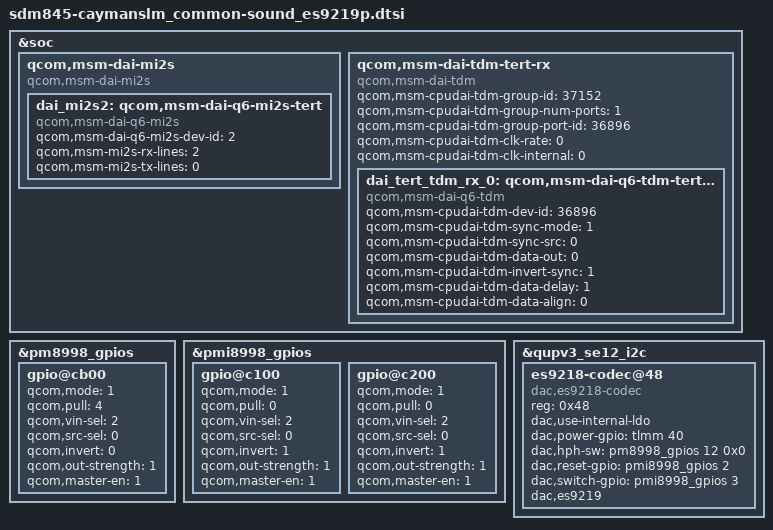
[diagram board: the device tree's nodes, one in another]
/* Copyright (c) 2017, The Linux Foundation. All rights reserved.
 *
 * This program is free software; you can redistribute it and/or modify
 * it under the terms of the GNU General Public License version 2 and
 * only version 2 as published by the Free Software Foundation.
 *
 * This program is distributed in the hope that it will be useful,
 * but WITHOUT ANY WARRANTY; without even the implied warranty of
 * MERCHANTABILITY or FITNESS FOR A PARTICULAR PURPOSE.  See the
 * GNU General Public License for more details.
 */

&soc {
	qcom,msm-dai-mi2s {
		compatible = "qcom,msm-dai-mi2s";
		dai_mi2s2: qcom,msm-dai-q6-mi2s-tert {
                       compatible = "qcom,msm-dai-q6-mi2s";
                       qcom,msm-dai-q6-mi2s-dev-id = <2>;
                       qcom,msm-mi2s-rx-lines = <2>; /* SD1 used as output */
                       qcom,msm-mi2s-tx-lines = <0>; /* SD0 used as input */
		};
	};

	qcom,msm-dai-tdm-tert-rx {
		compatible = "qcom,msm-dai-tdm";
		qcom,msm-cpudai-tdm-group-id = <37152>;
		qcom,msm-cpudai-tdm-group-num-ports = <1>;
		qcom,msm-cpudai-tdm-group-port-id = <36896>;
		qcom,msm-cpudai-tdm-clk-rate = <0>; // external clk
		qcom,msm-cpudai-tdm-clk-internal = <0>; /* EBIT */
		dai_tert_tdm_rx_0: qcom,msm-dai-q6-tdm-tert-rx-0 {
			compatible = "qcom,msm-dai-q6-tdm";
			qcom,msm-cpudai-tdm-dev-id = <36896>;
			qcom,msm-cpudai-tdm-sync-mode = <1>; /* long sync mode */
			qcom,msm-cpudai-tdm-sync-src = <0>; /* external source */
			qcom,msm-cpudai-tdm-data-out = <0>;
			qcom,msm-cpudai-tdm-invert-sync = <1>;
			qcom,msm-cpudai-tdm-data-delay = <1>;
			qcom,msm-cpudai-tdm-data-align = <0>;
		};
	};
};

&pm8998_gpios {
	gpio@cb00 { /* GPIO 12 - HIFI_MODE2 */
		qcom,mode = <1>;			/* Digital output */
		qcom,pull = <4>;			/* Pull down */
		qcom,vin-sel = <2>;			/* Vin 2 */
		qcom,src-sel = <0>;			/* Constant */
		qcom,invert = <0>;			/* Invert */
		qcom,out-strength = <1>;	/* Low */
		qcom,master-en = <1>;		/* Enable GPIO */
		status = "okay";
	};
};

&pmi8998_gpios {
	gpio@c100 { /* GPIO 2 - HIFI_RESET_N */
		qcom,mode = <1>;			/* Digital output*/
		qcom,pull = <0>;			/* Pull down 30uA */
		qcom,vin-sel = <2>;			/* VIN2 */
		qcom,src-sel = <0>;			/* Constant */
		qcom,invert = <1>;			/* Enable Invert */
		qcom,out-strength = <1>;	/* Low */
		qcom,master-en = <1>;		/* Enable GPIO */
		status = "okay";
	};
};

&pmi8998_gpios {
	gpio@c200 { /* GPIO 3 - HSDET_SWITCH_N */
		qcom,mode = <1>;			/* Digital output*/
		qcom,pull = <0>;			/* Pull down 30uA */
		qcom,vin-sel = <2>;			/* VIN2 */
		qcom,src-sel = <0>;			/* Constant */
		qcom,invert = <1>;			/* Enable Invert */
		qcom,out-strength = <1>;	/* Low */
		qcom,master-en = <1>;		/* Enable GPIO */
		status = "okay";
	};
};

&qupv3_se12_i2c { /*QUPV3 SE12 */
		status = "ok";
		es9218-codec@48{
			compatible = "dac,es9218-codec";
			status = "ok";
			reg = <0x48>;
			dac,use-internal-ldo;
			dac,power-gpio = <&tlmm 40 0x0>;
			dac,hph-sw = <&pm8998_gpios 12 0x0>;
			dac,reset-gpio = <&pmi8998_gpios 2 0x0>;
			dac,switch-gpio = <&pmi8998_gpios 3 0x0>;
			dac,es9219;
		};
};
